# STM32H562 register map
File version: 1.8
CPU: CM33 r0p0, little endian, MPU, FPU, 4 interrupt priority bits
Registers are 32-bit, read-write, reset 0x0 unless marked. A register's access mark holds for its fields unless they carry their own. Offsets are from the block's base; [hi:lo] are bit positions; {n}, {i} and the like mark numbered series.

## TIM12 — General-purpose timers
Base 0x40001800
Same registers: SEC_TIM12 0x50001800
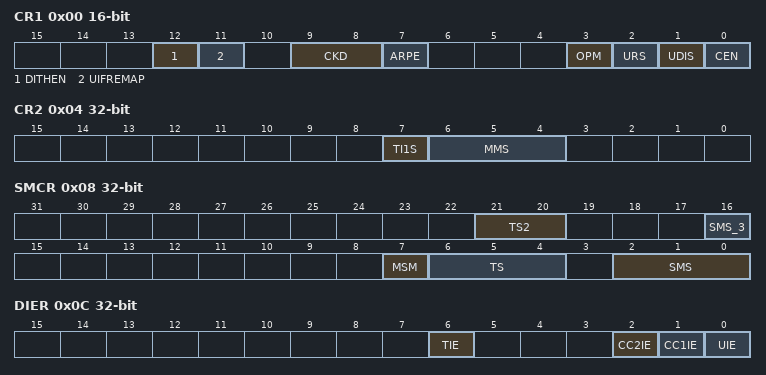
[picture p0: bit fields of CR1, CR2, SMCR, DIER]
0x00 CR1 16-bit — TIM12 control register 1
  [12] DITHEN — Dithering Enable Note: The DITHEN bit can only be modified when CEN bit is reset.
    0=Disabled (Dithering disabled); 1=Enabled (Dithering enabled)
  [11] UIFREMAP — UIF status bit remapping
    0=Disabled (No remapping. UIF status bit is not copied to TIMx_CNT register bit 31); 1=Enabled (Remapping enabled. UIF status bit is copied to TIMx_CNT register bit 31)
  [9:8] CKD — Clock division This bit-field indicates the division ratio between the timer clock (tim_ker_ck) frequency and sampling clock used by the digital filters (tim_etr_in, tim_tix),
    0=Div1 (t_DTS = t_CK_INT); 1=Div2 (t_DTS = 2 × t_CK_INT); 2=Div4 (t_DTS = 4 × t_CK_INT)
  [7] ARPE — Auto-reload preload enable
    0=Disabled (TIMx_APRR register is not buffered); 1=Enabled (TIMx_APRR register is buffered)
  [3] OPM — One-pulse mode
    0=Disabled (Counter is not stopped at update event); 1=Enabled (Counter stops counting at the next update event (clearing the CEN bit))
  [2] URS — Update request source This bit is set and cleared by software to select the UEV event sources. Counter overflow/underflow Setting the UG bit Update generation through the slave mode controller
    0=AnyEvent (Any of counter overflow/underflow, setting UG, or update through slave mode, generates an update interrupt or DMA request); 1=CounterOnly (Only counter overflow/underflow generates an update interrupt or DMA request)
  [1] UDIS — Update disable This bit is set and cleared by software to enable/disable UEV event generation. Counter overflow/underflow Setting the UG bit Update generation through the slave mode controller Buffered registers are then loaded with their preload values.
    0=Enabled (Update event enabled); 1=Disabled (Update event disabled)
  [0] CEN — Counter enable Note: External clock, gated mode and encoder mode can work only if the CEN bit has been previously set by software. However trigger mode can set the CEN bit automatically by hardware. CEN is cleared automatically in one-pulse mode, when an update event occurs.
    0=Disabled (Counter disabled); 1=Enabled (Counter enabled)
0x04 CR2 — TIM12 control register 2
  [7] TI1S — tim_ti1 selection
  [6:4] MMS — Master mode selection These bits allow to select the information to be sent in master mode to slave timers for synchronization (tim_trgo). The combination is as follows: tim_trgo, except if the master/slave mode is selected (see the MSM bit description in TIMx_SMCR register). Others: Reserved Note: The clock of the slave timer or ADC must be enabled prior to receive events from the master timer, and must not be changed on-the-fly while triggers are received from the master timer.
0x08 SMCR — TIM12 slave mode control register
  [21:20] TS2 — Trigger selection (see bits 21:20 for TS[4:3]) This bit-field selects the trigger input to be used to synchronize the counter. Others: Reserved See for product specific implementation details. Note: These bits must be changed only when they are not used (e.g. when SMS=000) to avoid wrong edge detections at the transition.
  [16] SMS_3 — Slave mode selection When external signals are selected the active edge of the trigger signal (tim_trgi) is linked to the polarity selected on the external input (see Input Control register and Control Register description. Note: The gated mode must not be used if tim_ti1f_ed is selected as the trigger input (TS=00100). Indeed, tim_ti1f_ed outputs 1 pulse for each transition on tim_ti1f, whereas the gated mode checks the level of the trigger signal. Note: The clock of the slave peripherals (timer, ADC, ...) receiving the tim_trgo signal must be enabled prior to receive events from the master timer, and the clock frequency (prescaler) must not be changed on-the-fly while triggers are received from the master timer.
  [7] MSM — Master/Slave mode
  [6:4] TS — Trigger selection (see bits 21:20 for TS[4:3]) This bit-field selects the trigger input to be used to synchronize the counter. Others: Reserved See for product specific implementation details. Note: These bits must be changed only when they are not used (e.g. when SMS=000) to avoid wrong edge detections at the transition.
  [2:0] SMS — Slave mode selection When external signals are selected the active edge of the trigger signal (tim_trgi) is linked to the polarity selected on the external input (see Input Control register and Control Register description. Note: The gated mode must not be used if tim_ti1f_ed is selected as the trigger input (TS=00100). Indeed, tim_ti1f_ed outputs 1 pulse for each transition on tim_ti1f, whereas the gated mode checks the level of the trigger signal. Note: The clock of the slave peripherals (timer, ADC, ...) receiving the tim_trgo signal must be enabled prior to receive events from the master timer, and the clock frequency (prescaler) must not be changed on-the-fly while triggers are received from the master timer.
0x0C DIER — TIM12 DMA/Interrupt enable register
  [6] TIE — Trigger interrupt enable
    0=Disabled (Trigger interrupt disabled); 1=Enabled (Trigger interrupt enabled)
  [n] CC{n}IE (n=1..2) — Capture/Compare {n} interrupt enable
    0=Disabled (CCx interrupt disabled); 1=Enabled (CCx interrupt enabled)
  [0] UIE — Update interrupt enable
    0=Disabled (Update interrupt disabled); 1=Enabled (Update interrupt enabled)
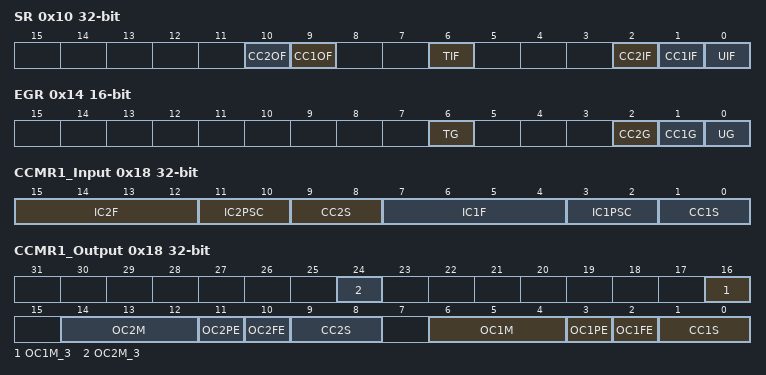
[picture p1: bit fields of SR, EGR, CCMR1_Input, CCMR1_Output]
0x10 SR — TIM12 status register
  [n+8] CC{n}OF (n=1..2) write-0-clears — Capture/Compare {n} overcapture flag
    on read: 0=No overcapture has been detected; 1=Overcapture (The counter value has been captured in TIMx_CCRx register while CCxIF flag was already set) | on write: 0=Clear flag
  [6] TIF write-0-clears — Trigger interrupt flag This flag is set by hardware on the TRG trigger event (active edge detected on tim_trgi input when the slave mode controller is enabled in all modes but gated mode. It is set when the counter starts or stops when gated mode is selected. It is cleared by software.
    on read: 0=No trigger event occurred; 1=Trigger interrupt pending | on write: 0=Clear flag
  [n] CC{n}IF (n=1..2) write-0-clears — Capture/compare {n} interrupt flag
    on read: 0=NoMatch (No campture/compare has been detected); 1=Match (If CC1 is an output: The content of the counter TIMx_CNT matches the content of the TIMx_CCR1 register. If CC1 is an input: The counter value has been captured in TIMx_CCR1 register.) | on write: 0=Clear flag
  [0] UIF write-0-clears — Update interrupt flag This bit is set by hardware on an update event. It is cleared by software. At overflow or underflow and if UDIS=0 in the TIMx_CR1 register. When CNT is reinitialized by software using the UG bit in TIMx_EGR register, if URS=0 and UDIS=0 in the TIMx_CR1 register. When CNT is reinitialized by a trigger event (refer to the synchro control register description), if URS=0 and UDIS=0 in the TIMx_CR1 register.
    on read: 0=NoUpdateOccurred; 1=UpdatePending (Update interrupt pending) | on write: 0=Clear flag
0x14 EGR 16-bit wo — TIM12 event generation register
  [6] TG — Trigger generation This bit is set by software in order to generate an event, it is automatically cleared by hardware.
    1=Trigger (The TIF flag is set in TIMx_SR register. Related interrupt or DMA transfer can occur if enabled.)
  [n] CC{n}G (n=1..2) — Capture/compare {n} generation
    1=Trigger (If CC1 is an output: CC1IF flag is set, Corresponding interrupt or DMA request is sent if enabled. If CC1 is an input: The current value of the counter is captured in TIMx_CCR1 register.)
  [0] UG — Update generation This bit can be set by software, it is automatically cleared by hardware.
    1=Update (Re-initializes the timer counter and generates an update of the registers.)
0x18 CCMR1_Input — TIM12 capture/compare mode register 1 [alternate]
  [9:8] CC2S — Capture/compare 2 selection This bit-field defines the direction of the channel (input/output) as well as the used input. Note: CC2S bits are writable only when the channel is OFF (CC2E = 0 in TIMx_CCER).
    1=TI2 (CC2 channel is configured as input, IC2 is mapped on TI2); 2=TI1 (CC2 channel is configured as input, IC2 is mapped on TI1); 3=TRC (CC2 channel is configured as input, IC2 is mapped on TRC)
  [8n-1:8n-4] IC{n}F (n=1..2) — Input capture {n} filter
    0=No filter, sampling is done at fDTS; 1=FCK_INT_N2 (fSAMPLING=fCK_INT, N=2); 2=FCK_INT_N4 (fSAMPLING=fCK_INT, N=4); 3=FCK_INT_N8 (fSAMPLING=fCK_INT, N=8); 4=FDTS_Div2_N6 (fSAMPLING=fDTS/2, N=6); 5=FDTS_Div2_N8 (fSAMPLING=fDTS/2, N=8); 6=FDTS_Div4_N6 (fSAMPLING=fDTS/4, N=6); 7=FDTS_Div4_N8 (fSAMPLING=fDTS/4, N=8); 8=FDTS_Div8_N6 (fSAMPLING=fDTS/8, N=6); 9=FDTS_Div8_N8 (fSAMPLING=fDTS/8, N=8); 10=FDTS_Div16_N5 (fSAMPLING=fDTS/16, N=5); 11=FDTS_Div16_N6 (fSAMPLING=fDTS/16, N=6); 12=FDTS_Div16_N8 (fSAMPLING=fDTS/16, N=8); 13=FDTS_Div32_N5 (fSAMPLING=fDTS/32, N=5); 14=FDTS_Div32_N6 (fSAMPLING=fDTS/32, N=6); 15=FDTS_Div32_N8 (fSAMPLING=fDTS/32, N=8)
  [8n-5:8n-6] IC{n}PSC (n=1..2) — Input capture {n} prescaler
    0=No prescaler, capture is done each time an edge is detected on the capture input; 1=TwoEvents (Capture is done once every 2 events); 2=FourEvents (Capture is done once every 4 events); 3=EightEvents (Capture is done once every 8 events)
  [1:0] CC1S — Capture/Compare 1 selection This bit-field defines the direction of the channel (input/output) as well as the used input. Note: CC1S bits are writable only when the channel is OFF (CC1E = 0 in TIMx_CCER).
    1=TI1 (CC1 channel is configured as input, IC1 is mapped on TI1); 2=TI2 (CC1 channel is configured as input, IC1 is mapped on TI2); 3=TRC (CC1 channel is configured as input, IC1 is mapped on TRC)
0x18 CCMR1_Output (alternate view of CCMR1_Input) — TIM12 capture/compare mode register 1 [alternate]
  [8n+8] OC{n}M_3 (n=1..2) — Output compare {n} mode, bit 3
    0=Normal output compare mode (modes 0-7); 1=Extended output compare mode (modes 7-15)
  [8n-2:8n-4] OC{n}M (n=1..2) — Output compare {n} mode
    0=Frozen (The comparison between the output compare register TIMx_CCRy and the counter TIMx_CNT has no effect on the outputs / OpmMode1: Retriggerable OPM mode 1 - In up-counting mode, the channel is active until a trigger event is detected (on TRGI signal). In down-counting mode, the channel is inactive); 1=ActiveOnMatch (Set channel to active level on match. OCyREF signal is forced high when the counter matches the capture/compare register / OpmMode2: Inversely to OpmMode1); 2=InactiveOnMatch (Set channel to inactive level on match. OCyREF signal is forced low when the counter matches the capture/compare register / Reserved); 3=Toggle (OCyREF toggles when TIMx_CNT=TIMx_CCRy / Reserved); 4=ForceInactive (OCyREF is forced low / CombinedPwmMode1: OCyREF has the same behavior as in PWM mode 1. OCyREFC is the logical OR between OC1REF and OC2REF); 5=ForceActive (OCyREF is forced high / CombinedPwmMode2: OCyREF has the same behavior as in PWM mode 2. OCyREFC is the logical AND between OC1REF and OC2REF); 6=PwmMode1 (In upcounting, channel is active as long as TIMx_CNT<TIMx_CCRy else inactive. In downcounting, channel is inactive as long as TIMx_CNT>TIMx_CCRy else active / Reserved); 7=PwmMode2 (Inversely to PwmMode1 / Reserved)
  [8n-5] OC{n}PE (n=1..2) — Output compare {n} preload enable
    0=Disabled (Preload register on CCRx disabled. New values written to CCRx are taken into account immediately); 1=Enabled (Preload register on CCRx enabled. Preload value is loaded into active register on each update event)
  [8n-6] OC{n}FE (n=1..2) — Output compare {n} fast enable
    0=Disabled (Fast output disabled); 1=Enabled (Fast output enabled)
  [8n-7:8n-8] CC{n}S (n=1..2) — Capture/Compare {n} selection
    0=Output (CCx channel is configured as output)
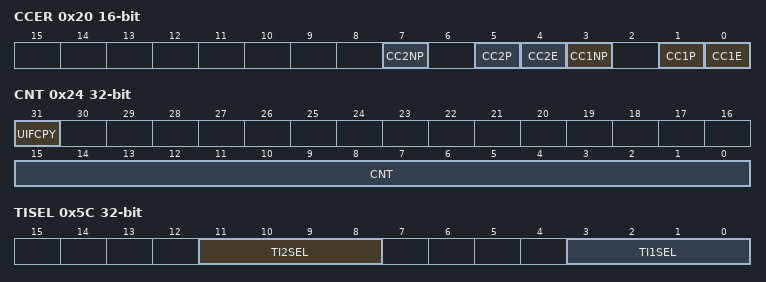
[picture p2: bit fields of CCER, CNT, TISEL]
0x20 CCER 16-bit — TIM12 capture/compare enable register
  [4n-1] CC{n}NP (n=1..2) — Capture/Compare {n} output Polarity
  [4n-3] CC{n}P (n=1..2) — Capture/Compare {n} output Polarity
    0=RisingEdge (Noninverted/rising edge); 1=FallingEdge (Inverted/falling edge)
  [4n-4] CC{n}E (n=1..2) — Capture/Compare {n} output enable
    0=Disabled (Capture disabled); 1=Enabled (Capture enabled)
0x24 CNT — TIM12 counter
  [31] UIFCPY — UIF Copy
    on read: 0=NoUpdateOccurred; 1=UpdatePending (Update interrupt pending)
  [15:0] CNT — or UIFCPY: Value depends on IUFREMAP in TIMx_CR1. If UIFREMAP = 0 nullMost significant bit of counter value If UIFREMAP = 1 UIFCPY: UIF Copy This bit is a read-only copy of the UIF bit of the TIMx_ISR register nullLeast significant part of counter value Non-dithering mode (DITHEN = 0) The register holds the counter value. Dithering mode (DITHEN = 1) The register holds the non-dithered part in CNT[30:0]. The fractional part is not available.
0x28 PSC 16-bit — TIM12 prescaler
  [15:0] PSC — Prescaler value The counter clock frequency tim_cnt_ck is equal to ftim_psc_ck / (PSC[15:0] + 1). PSC contains the value to be loaded in the active prescaler register at each update event (including when the counter is cleared through UG bit of TIMx_EGR register or through trigger controller when configured in 'reset mode').
0x2C ARR reset 0xFFFFFFFF — TIM12 auto-reload register
  [19:0] ARR — Auto-reload value ARR is the value to be loaded in the actual auto-reload register. Refer to the for more details about ARR update and behavior. The counter is blocked while the auto-reload value is null. Non-dithering mode (DITHEN = 0) The register holds the auto-reload value. Dithering mode (DITHEN = 1) The register holds the integer part in ARR[31:4]. The ARR[3:0] bitfield contains the dithered part.
{0x30+4i} CCR{i} (i=1..2) — capture/compare register
  [19:0] CCR — Capture/Compare value
0x5C TISEL — TIM12 timer input selection register
  [11:8] TI2SEL — Selects tim_ti2[0..15] input ... Refer to for product specific implementation.
  [3:0] TI1SEL — Selects tim_ti1[0..15] input ... Refer to for product specific implementation.
